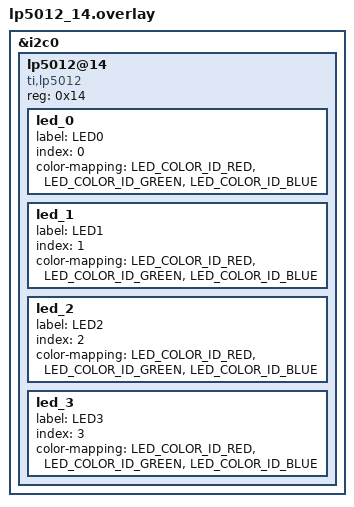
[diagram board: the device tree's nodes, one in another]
/* SPDX-License-Identifier: Apache-2.0 OR MIT */
/*
 * A TI LP5012 at 0x14 (ADDR1-ADDR0 low, SLVSEH2B Table 8-3) on I2C0
 * (i2c0.overlay): its four RGB modules as four LEDs.
 */
#include <zephyr/dt-bindings/led/led.h>

&i2c0 {
	lp5012@14 {
		compatible = "ti,lp5012";
		reg = <0x14>;

		led_0 {
			label = "LED0";
			index = <0>;
			color-mapping = <LED_COLOR_ID_RED>,
					<LED_COLOR_ID_GREEN>,
					<LED_COLOR_ID_BLUE>;
		};

		led_1 {
			label = "LED1";
			index = <1>;
			color-mapping = <LED_COLOR_ID_RED>,
					<LED_COLOR_ID_GREEN>,
					<LED_COLOR_ID_BLUE>;
		};

		led_2 {
			label = "LED2";
			index = <2>;
			color-mapping = <LED_COLOR_ID_RED>,
					<LED_COLOR_ID_GREEN>,
					<LED_COLOR_ID_BLUE>;
		};

		led_3 {
			label = "LED3";
			index = <3>;
			color-mapping = <LED_COLOR_ID_RED>,
					<LED_COLOR_ID_GREEN>,
					<LED_COLOR_ID_BLUE>;
		};
	};
};
